# STM32U3B5xx register map
File version: 1.0
Registers are 32-bit, read-write, reset 0x0 unless marked. A register's access mark holds for its fields unless they carry their own. Offsets are from the block's base; [hi:lo] are bit positions; {n}, {i} and the like mark numbered series.

## HASH
Base 0x420C0400
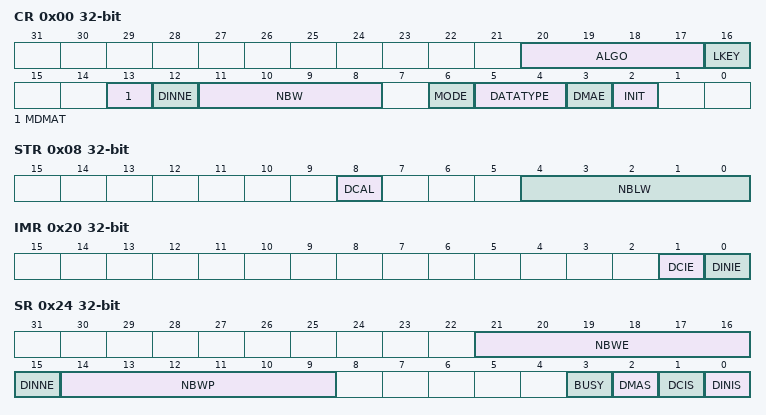
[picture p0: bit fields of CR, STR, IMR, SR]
0x00 CR — HASH control register
  [20:17] ALGO, [16] LKEY, [13] MDMAT, [12] DINNE, [11:8] NBW, [6] MODE, [5:4] DATATYPE, [3] DMAE, [2] INIT
0x04 DIN — HASH data input register
0x08 STR — HASH start register
  [8] DCAL, [4:0] NBLW
{0xC+4i} HR{i} (i=0..4) — HASH digest registers
0x20 IMR — HASH interrupt enable register
  [1] DCIE, [0] DINIE
0x24 SR — HASH status register
  [21:16] NBWE, [15] DINNE, [14:9] NBWP, [3] BUSY, [2] DMAS, [1] DCIS, [0] DINIS
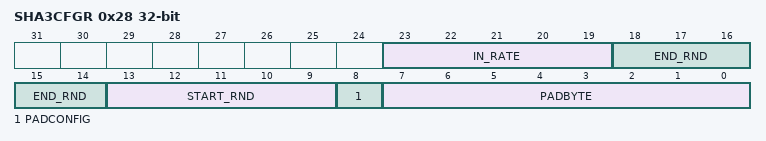
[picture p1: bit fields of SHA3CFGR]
0x28 SHA3CFGR — HASH SHA-3 configuration register
  [23:19] IN_RATE, [18:14] END_RND, [13:9] START_RND, [8] PADCONFIG, [7:0] PADBYTE
{0xF8+4i} CSR[{i}] (i=0..102)
{0x310+4i} DIGEST_HR{i} (i=0..49) — HASH digest registers

## RNG
Base 0x420C0800
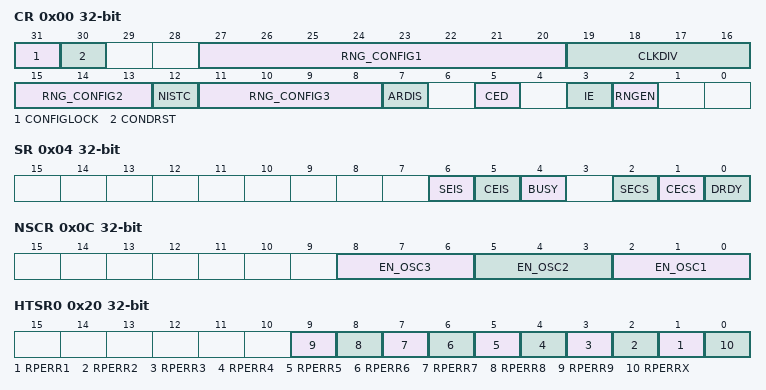
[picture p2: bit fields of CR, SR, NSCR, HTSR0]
0x00 CR — RNG control register
  [31] CONFIGLOCK — RNG configuration lock
  [30] CONDRST — Conditioning soft reset
  [27:20] RNG_CONFIG1 — RNG configuration 1
  [19:16] CLKDIV — Clock divider factor
    0=BY_1 (No clock division); 1=BY_2 (2 RNG clock cycles per internal RNG clock); 2=BY_4 (4 RNG clock cycles per internal RNG clock); 3=BY_8 (8 RNG clock cycles per internal RNG clock); 4=BY_16 (16 RNG clock cycles per internal RNG clock); 5=BY_32 (32 RNG clock cycles per internal RNG clock); 6=BY_64 (64 RNG clock cycles per internal RNG clock); 7=BY_128 (128 RNG clock cycles per internal RNG clock); 8=BY_256 (256 RNG clock cycles per internal RNG clock); 9=BY_512 (512 RNG clock cycles per internal RNG clock); 10=BY_1024 (1024 RNG clock cycles per internal RNG clock); 11=BY_2048 (2048 RNG clock cycles per internal RNG clock); 12=BY_4096 (4096 RNG clock cycles per internal RNG clock); 13=BY_8192 (8192 RNG clock cycles per internal RNG clock); 14=BY_16384 (16384 RNG clock cycles per internal RNG clock); 15=BY_32768 (32768 RNG clock cycles per internal RNG clock)
  [15:13] RNG_CONFIG2 — RNG configuration 2
  [12] NISTC — NIST custom
  [11:8] RNG_CONFIG3 — RNG configuration 3
  [7] ARDIS — Auto reset disable
  [5] CED — Clock error detection
  [3] IE — Interrupt enable
  [2] RNGEN — True random number generator enable
0x04 SR — RNG status register
  [6] SEIS, [5] CEIS, [4] BUSY, [2] SECS, [1] CECS, [0] DRDY
0x08 DR — RNG data register
0x0C NSCR — RNG noise source control register
  [8:6] EN_OSC3, [5:3] EN_OSC2, [2:0] EN_OSC1
{0x10+4i} HTCR{i} (i=0..3) — RNG health test configuration register
  [31:0] HTCFG
0x20 HTSR0 — RNG health test status register
  [n] RPERR{n} (n=1..9) — Repetitive error for oscillator i
  [0] RPERRX — Repetitive error after the XOR
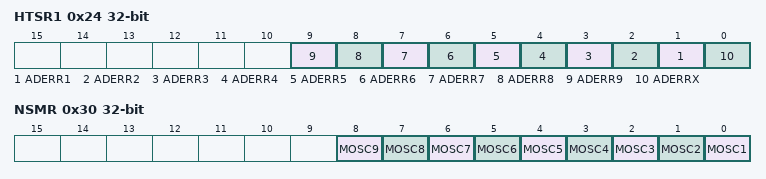
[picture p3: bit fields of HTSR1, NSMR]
0x24 HTSR1 — RNG health test status register
  [n] ADERR{n} (n=1..9) — Adaptative error for oscillator i
  [0] ADERRX — Adaptative error after the XOR
0x30 NSMR — RNG health test status register
  [n-1] MOSC{n} (n=1..9) — Mask oscillator i

## PKA
Base 0x420C2000
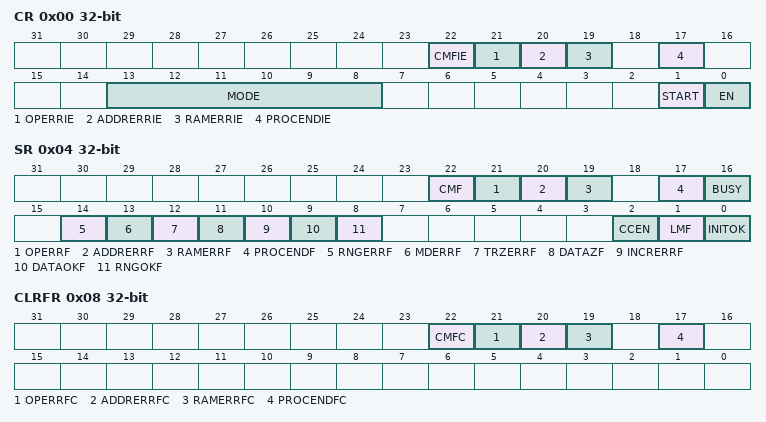
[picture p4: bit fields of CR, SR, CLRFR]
0x00 CR — PKA control register
  [22] CMFIE — Chaining mode flags interrupt enable
  [21] OPERRIE — Operation Error interrupt enable
  [20] ADDRERRIE — Address error interrupt enable
  [19] RAMERRIE — RAM error interrupt enable
  [17] PROCENDIE — End of operation interrupt enable
  [13:8] MODE — MODE[5:0] PKA operation code
  [1] START — Start operation
  [0] EN — PKA enable
0x04 SR — PKA status register
  [22] CMF — Chaining mode flag
  [21] OPERRF — PKA operation Error flag
  [20] ADDRERRF — Address error flag
  [19] RAMERRF — PKA RAM error flag
  [17] PROCENDF — PKA end of operation flag
  [16] BUSY — PKA operation is in progress
  [14] RNGERRF — PKA RNG error flag
  [13] MDERRF — PKA Mode error flag
  [12] TRZERRF — PKA Trailing zeros error flag
  [11] DATAZF — PKA Data zeroed error flag
  [10] INCRERRF — PKA Increment error flag
  [9] DATAOKF — PKA Data OK flag
  [8] RNGOKF — PKA RNG OK flag
  [2] CCEN — PKA Coupling and chaining mode enable
  [1] LMF — PKA Limited mode flag
  [0] INITOK — PKA initialisation flag
0x08 CLRFR — PKA clear flag register
  [22] CMFC — Clear chaining mode flag
  [21] OPERRFC — Clear PKA operation Error flag
  [20] ADDRERRFC — Clear address error flag
  [19] RAMERRFC — Clear PKA RAM error flag
  [17] PROCENDFC — Clear PKA end of operation flag
{0x400+4i} RAM[{i}] (i=0..1333)

## DLYB_SDMMC1
Base 0x420C8400
Same registers: DLYB_OCTOSPI1 0x420CF000
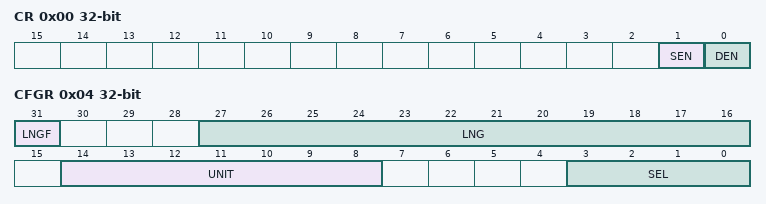
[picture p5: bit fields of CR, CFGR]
0x00 CR — Delay Block Control Register
  [1] SEN — Sampler length enable
  [0] DEN — Delay Block enable
0x04 CFGR — Delay Block Configuration Register
  [31] LNGF — Length valid flag
  [27:16] LNG — Delay line length value[11:0]
  [14:8] UNIT — Delay Defines the delay of a Unit delay cell[6:0]
  [3:0] SEL — Select the phase for the Output clock[3:0]

## DBGMCU — Debug MCU
Base 0xE0044000
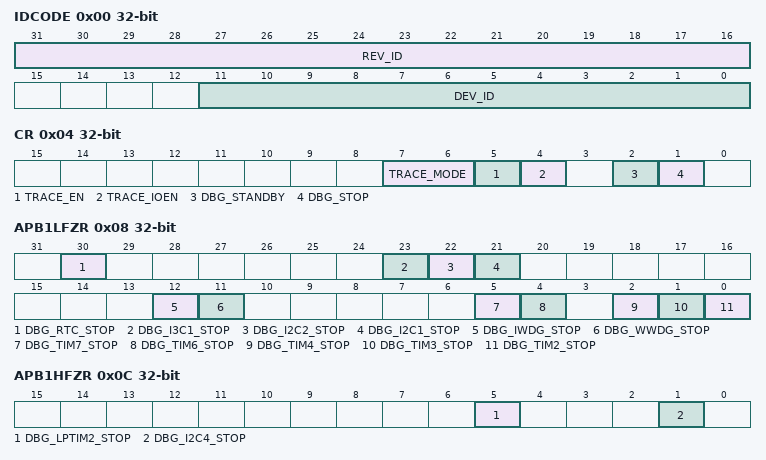
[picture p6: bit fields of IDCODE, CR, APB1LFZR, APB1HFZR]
0x00 IDCODE — MCU device ID code
  [31:16] REV_ID, [11:0] DEV_ID
0x04 CR — Debug MCU configuration register
  [7:6] TRACE_MODE, [5] TRACE_EN, [4] TRACE_IOEN, [2] DBG_STANDBY, [1] DBG_STOP
0x08 APB1LFZR — Debug MCU APB1L freeze register
  [30] DBG_RTC_STOP, [23] DBG_I3C1_STOP, [22] DBG_I2C2_STOP, [21] DBG_I2C1_STOP, [12] DBG_IWDG_STOP, [11] DBG_WWDG_STOP, [5] DBG_TIM7_STOP, [4] DBG_TIM6_STOP, [2] DBG_TIM4_STOP, [1] DBG_TIM3_STOP, [0] DBG_TIM2_STOP
0x0C APB1HFZR — Debug MCU APB1H freeze register
  [5] DBG_LPTIM2_STOP, [1] DBG_I2C4_STOP
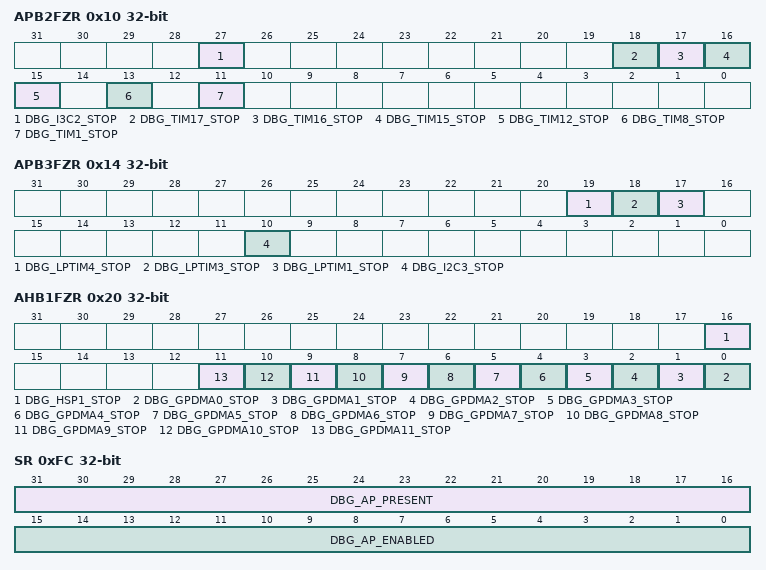
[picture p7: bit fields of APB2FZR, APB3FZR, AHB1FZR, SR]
0x10 APB2FZR — Debug MCU APB2 freeze register
  [27] DBG_I3C2_STOP, [18] DBG_TIM17_STOP, [17] DBG_TIM16_STOP, [16] DBG_TIM15_STOP, [15] DBG_TIM12_STOP, [13] DBG_TIM8_STOP, [11] DBG_TIM1_STOP
0x14 APB3FZR — Debug MCU APB3 freeze register
  [19] DBG_LPTIM4_STOP, [18] DBG_LPTIM3_STOP, [17] DBG_LPTIM1_STOP, [10] DBG_I2C3_STOP
0x20 AHB1FZR — Debug MCU AHB1 freeze register
  [16] DBG_HSP1_STOP, [n] DBG_GPDMA{n}_STOP (n=0..11)
0xFC SR — Debug MCU status register
  [31:16] DBG_AP_PRESENT, [15:0] DBG_AP_ENABLED
0x100 DGB_AUTH_HOST — Debug MCU debug host authentication register
0x104 DGB_AUTH_DEVICE — Debug MCU debug device authentication register
0xFD0 PIDR4 — Debug MCU CoreSight peripheral identity register 4
  [3:0] JEP106CON
0xFD4 PIDR0 — Debug MCU CoreSight peripheral identity register 0
  [7:0] PARTNUM
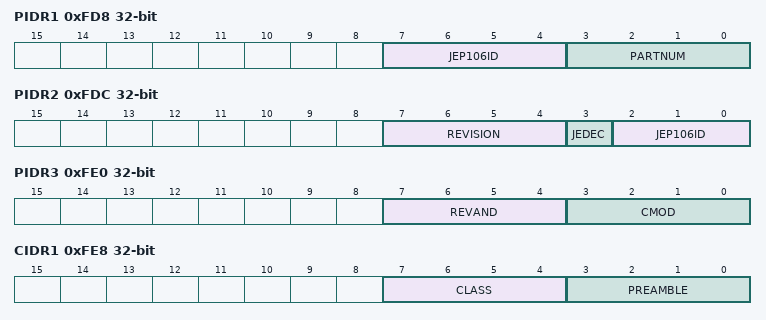
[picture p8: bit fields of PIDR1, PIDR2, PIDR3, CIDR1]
0xFD8 PIDR1 — Debug MCU CoreSight peripheral identity register 1
  [7:4] JEP106ID, [3:0] PARTNUM
0xFDC PIDR2 — Debug MCU CoreSight peripheral identity register 2
  [7:4] REVISION, [3] JEDEC, [2:0] JEP106ID
0xFE0 PIDR3 — Debug MCU CoreSight peripheral identity register 3
  [7:4] REVAND, [3:0] CMOD
0xFE4 CIDR0 — Debug MCU CoreSight component identity register 0
  [7:0] PREAMBLE
0xFE8 CIDR1 — Debug MCU CoreSight component identity register 1
  [7:4] CLASS, [3:0] PREAMBLE
0xFEC CIDR2 — Debug MCU CoreSight component identity register 2
  [7:0] PREAMBLE
0xFF0 CIDR3 — Debug MCU CoreSight component identity register 3
  [7:0] PREAMBLE
